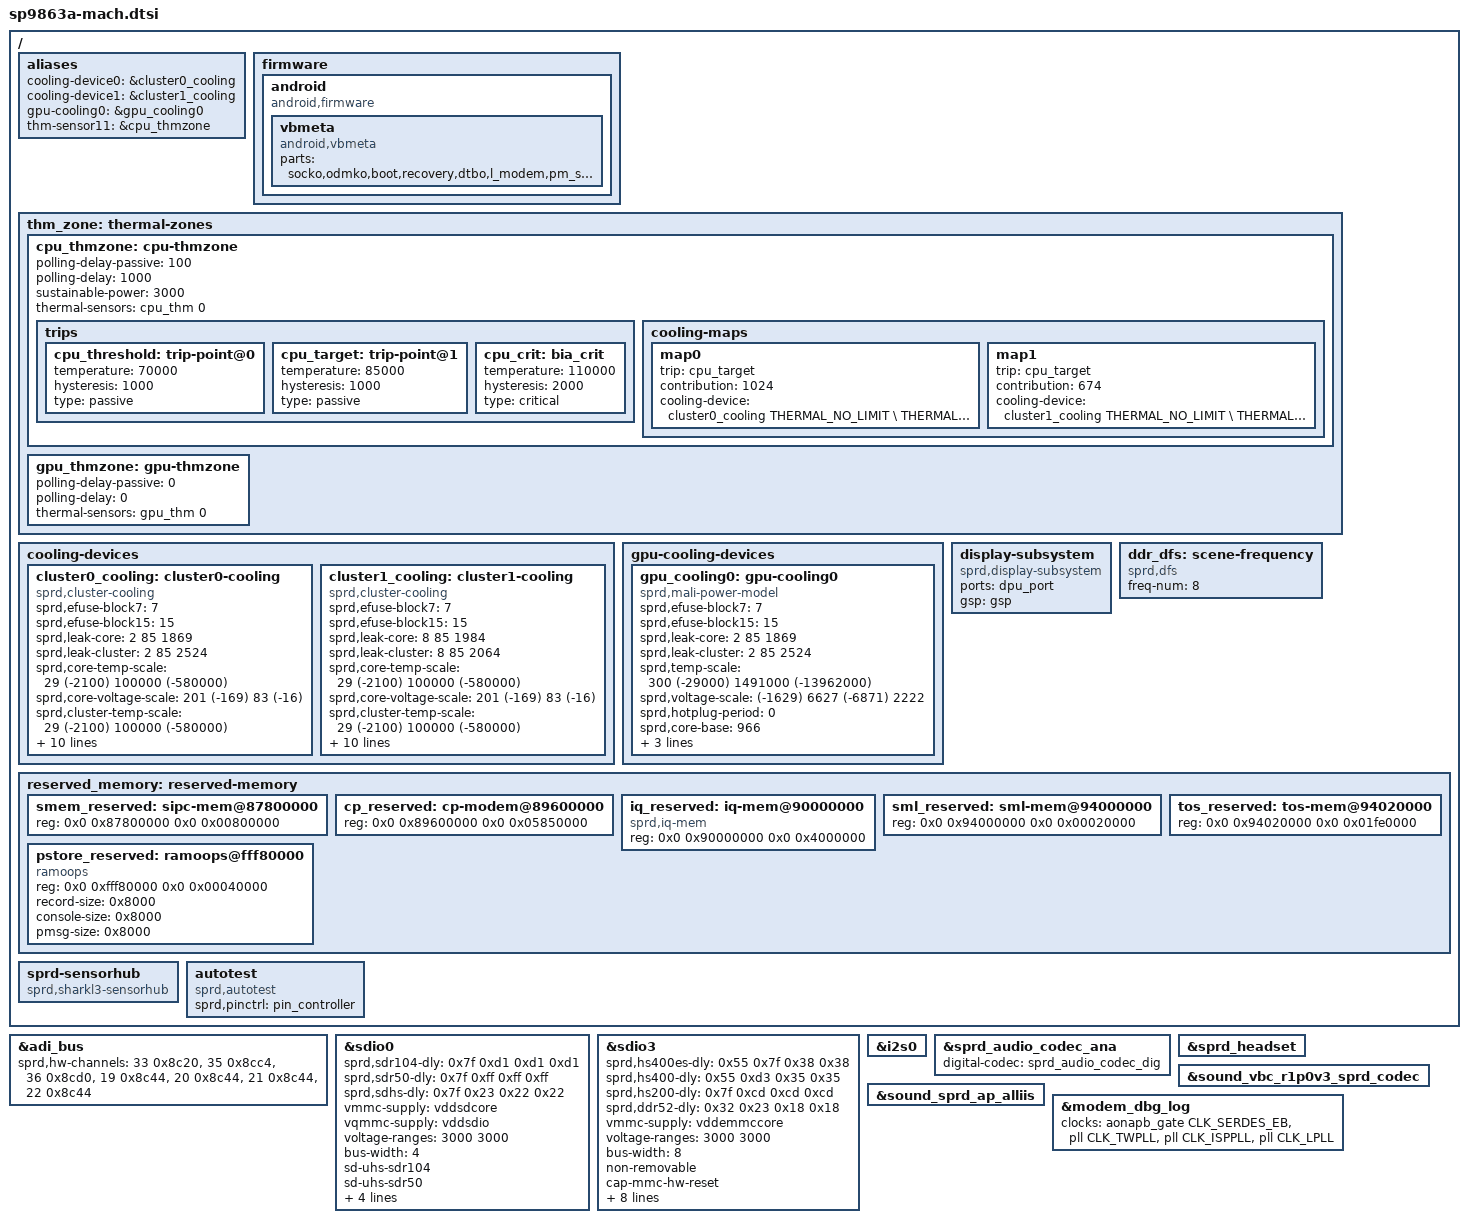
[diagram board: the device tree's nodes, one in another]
/*
 * Spreadtrum SP9863A board common DTS file
 *
 * Copyright (C) 2017, Spreadtrum Communications Inc.
 *
 * This file is licensed under a dual GPLv2 or X11 license.
 */

#include "sc9863a-modem.dtsi"
#include "sc2721.dtsi"
#include "lcd/lcd_dummy_mipi.dtsi"
#include "sprd-sound-sharkl.dtsi"
#include <dt-bindings/thermal/thermal.h>

/ {
	aliases {
		cooling-device0 = &cluster0_cooling;
		cooling-device1 = &cluster1_cooling;
		gpu-cooling0 = &gpu_cooling0;
		thm-sensor11 = &cpu_thmzone;
	};

	firmware {
		android {
			compatible = "android,firmware";
			vbmeta {
				compatible = "android,vbmeta";
				parts = "socko,odmko,boot,recovery,dtbo,l_modem,pm_sys,l_ldsp,l_gdsp";
			};
		};
	};

	thm_zone: thermal-zones {

		cpu_thmzone: cpu-thmzone {
			polling-delay-passive = <100>;
			polling-delay = <1000>;
			sustainable-power = <3000>;
			thermal-sensors = <&cpu_thm  0>;
			trips {
				cpu_threshold: trip-point@0 {
					temperature = <70000>;
					hysteresis = <1000>;
					type = "passive";
				};
				cpu_target: trip-point@1 {
					temperature = <85000>;
					hysteresis = <1000>;
					type = "passive";
				};
				cpu_crit: bia_crit {
					temperature = <110000>;
					hysteresis = <2000>;
					type = "critical";
				};
			};
			cooling-maps {
				map0 {
					trip = <&cpu_target>;
					contribution = <1024>;
					cooling-device =
					<&cluster0_cooling THERMAL_NO_LIMIT \
					THERMAL_NO_LIMIT>;
				};
				map1 {
					trip = <&cpu_target>;
					contribution = <674>;
					cooling-device =
					<&cluster1_cooling THERMAL_NO_LIMIT \
					THERMAL_NO_LIMIT>;
				};
			};
		};

		gpu_thmzone: gpu-thmzone {
			polling-delay-passive = <0>;
			polling-delay = <0>;
			thermal-sensors = <&gpu_thm  0>;
		};
	};

	cooling-devices {
		cluster0_cooling: cluster0-cooling {
			compatible = "sprd,cluster-cooling";
			#cooling-cells = <2>; /* min followed by max */
			sprd,efuse-block7 = <7>;
			sprd,efuse-block15 = <15>;
			/* core_leak =                             */
			/*(LIT_LEAK[4:0]+1) x 2mA x 0.85V x 18.69% */
			sprd,leak-core = <2 85 1869>;
			/* cluster_leak =                           */
			/* (LIT_LEAK[4:0]+1) x 2mA x 0.85V x 25.24% */
			sprd,leak-cluster = <2 85 2524>;
			/*core Tscale = aT^3 + bT^2 + cT +di   */
			sprd,core-temp-scale =
			/* a*10^7   b*10^7      c*10^7     d*10^7 */
			<  29      (-2100)      100000    (-580000)>;
			/*core Vscale = eV^3 + fV^2 + gV + h */
			sprd,core-voltage-scale =
			/* e*10^2   f*10^2     g*10^2  h*10^2*/
			<  201     (-169)      83      (-16)>;
			/*cluster Tscale = aT^3 + bT^2 + cT +di   */
			sprd,cluster-temp-scale =
			/* a*10^7   b*10^7      c*10^7     d*10^7 */
			<  29      (-2100)      100000    (-580000)>;
			/*cluster Vscale = eV^3 + fV^2 + gV + h */
			sprd,cluster-voltage-scale =
			/* e*10^2   f*10^2     g*10^2  h*10^2*/
			<  201     (-169)      83      (-16)>;
			sprd,efuse-switch = <0>;
			sprd,hotplug-period = <10>;
			sprd,min-cpufreq = <768000>;
			sprd,min-cpunum = <4>;
			sprd,core-base = <2400>;
			sprd,cluster-base = <3970>;
			sprd,dynamic-core =
			/*Pdynperghz*10    Freq     Vbase  */
			< 1007           1000     1000>;
			sprd,dynamic-cluster =
			/*Pdynperghz*10    Freq     Vbase  */
			< 747           1000     1000>;
		};
		cluster1_cooling: cluster1-cooling {
			compatible = "sprd,cluster-cooling";
			#cooling-cells = <2>; /* min followed by max */
			sprd,efuse-block7 = <7>;
			sprd,efuse-block15 = <15>;
			/* core_leak =                             */
			/*(LIT_LEAK[4:0]+1) x 2mA x 0.85V x 18.69% */
			sprd,leak-core = <8 85 1984>;
			/* cluster_leak =                           */
			/* (LIT_LEAK[4:0]+1) x 2mA x 0.85V x 25.24% */
			sprd,leak-cluster = <8 85 2064>;
			/*core Tscale = aT^3 + bT^2 + cT +d  */
			sprd,core-temp-scale =
			/* a*10^7   b*10^7	c*10^7	   d*10^7*/
			<  29      (-2100)      100000    (-580000)>;
			/* core  Vscale = eV^3 + fV^2 + gV + h */
			sprd,core-voltage-scale =
			/* e*10^2  f*10^2     g*10^2  h*10^2*/
			<  201     (-169)      83      (-16)>;
			/*cluster Tscale = aT^3 + bT^2 + cT +di   */
			sprd,cluster-temp-scale =
			/* a*10^7   b*10^7      c*10^7     d*10^7 */
			<  29      (-2100)      100000    (-580000)>;
			/*cluster Vscale = eV^3 + fV^2 + gV + h */
			sprd,cluster-voltage-scale =
			/* e*10^2   f*10^2     g*10^2  h*10^2*/
			<  201     (-169)      83      (-16)>;
			sprd,efuse-switch = <0>;
			sprd,hotplug-period = <10>;
			sprd,min-cpufreq = <768000>;
			sprd,min-cpunum = <0>;
			sprd,core-base = <4190>;
			sprd,cluster-base = <3970>;
			sprd,dynamic-core =
			/* Pdynperghz*10    Freq     Vbase */
			<  1536          1000     1000>;
			sprd,dynamic-cluster =
			/* Pdynperghz*10    Freq     Vbase */
			<  747            1000     1000>;
		};
	};

	gpu-cooling-devices {
		gpu_cooling0: gpu-cooling0 {
			compatible = "sprd,mali-power-model";
			#cooling-cells = <2>;
			sprd,efuse-block7 = <7>;
			sprd,efuse-block15 = <15>;
			/* core_leak =                             */
			/*(LIT_LEAK[4:0]+1) x 2mA x 0.85V x 18.69% */
			sprd,leak-core = <2 85 1869>;
			/* cluster_leak =                           */
			/* (LIT_LEAK[4:0]+1) x 2mA x 0.85V x 25.24% */
			sprd,leak-cluster = <2 85 2524>;
			/*Tscale = aT^3 + bT^2 + cT +di   */
			sprd,temp-scale =
			/* a*10^7   b*10^7      c*10^7     d*10^7 */
			<  300     (-29000)     1491000    (-13962000)>;
			/*Vscale = eV^3 + fV^2 + gV + h */
			sprd,voltage-scale =
			/* e*10^2   f*10^2     g*10^2      h*10^2*/
			<  (-1629)  6627       (-6871)     2222>;
			sprd,hotplug-period = <0>;
			sprd,core-base = <966>;
			sprd,cluster-base = <966>;
			sprd,dynamic-core =
			/*Pdynperghz    Freq     Vbase  */
			< 6046           768     900>;
			sprd,dynamic-cluster =
			/*Pdynperghz    Freq     Vbase  */
			< 6064           768     900>;
		};
	};

	display-subsystem {
		compatible = "sprd,display-subsystem";
		ports = <&dpu_port>;
		gsp = <&gsp>;
	};

	ddr_dfs: scene-frequency {
		compatible = "sprd,dfs";
		freq-num = <8>;
	};

	reserved_memory: reserved-memory {
		#address-cells = <2>;
		#size-cells = <2>;
		ranges;

		smem_reserved: sipc-mem@87800000{
			reg = <0x0 0x87800000 0x0 0x00800000>;
		};

		cp_reserved: cp-modem@89600000 {
			reg = <0x0 0x89600000 0x0 0x05850000>;
		};

		/* Only used for iq, will be removed in normal mode by uboot */
		iq_reserved: iq-mem@90000000 {
			compatible = "sprd,iq-mem";
			reg = <0x0 0x90000000 0x0 0x4000000>;
		};

		/* must be 1M aligned */
		sml_reserved: sml-mem@94000000 {
			reg = <0x0 0x94000000 0x0 0x00020000>;
		};

		tos_reserved: tos-mem@94020000{
			reg = <0x0 0x94020000 0x0 0x01fe0000>;
		};

		pstore_reserved: ramoops@fff80000 {
			compatible = "ramoops";
			reg = <0x0 0xfff80000 0x0 0x00040000>;
			record-size = <0x8000>;
			console-size = <0x8000>;
			pmsg-size = <0x8000>;
		};
	};

	sprd-sensorhub {
		compatible = "sprd,sharkl3-sensorhub";
	};

	autotest: autotest {
		compatible = "sprd,autotest";
		sprd,pinctrl = <&pin_controller>;
	};
};

&adi_bus {
	sprd,hw-channels = <33 0x8c20>, <35 0x8cc4>, <36 0x8cd0>, <19 0x8c44>, <20 0x8c44>, <21 0x8c44>, <22 0x8c44>;
};

&sdio0 {
	sprd,sdr104-dly = <0x7f 0xd1 0xd1 0xd1>;
	sprd,sdr50-dly = <0x7f 0xff 0xff 0xff>;
	sprd,sdhs-dly = <0x7f 0x23 0x22 0x22>;
	vmmc-supply = <&vddsdcore>;
	vqmmc-supply = <&vddsdio>;
	voltage-ranges = <3000 3000>;
	bus-width = <4>;
	sd-uhs-sdr104;
	sd-uhs-sdr50;
	sprd,name = "sdio_sd";
	sprd,sdio-adma;
	no-sdio;
	no-mmc;
	status = "okay";
};

&sdio3 {
	sprd,hs400es-dly = <0x55 0x7f 0x38 0x38>;
	sprd,hs400-dly = <0x55 0xd3 0x35 0x35>;
	sprd,hs200-dly = <0x7f 0xcd 0xcd 0xcd>;
	sprd,ddr52-dly = <0x32 0x23 0x18 0x18>;
	vmmc-supply = <&vddemmccore>;
	voltage-ranges = <3000 3000>;
	bus-width = <8>;
	non-removable;
	cap-mmc-hw-reset;
	mmc-hs400-enhanced-strobe;
	mmc-hs400-1_8v;
	mmc-hs200-1_8v;
	mmc-ddr-1_8v;
	sprd,name = "sdio_emmc";
	sprd,sdio-adma;
	no-sdio;
	no-sd;
	status = "okay";
};

&i2s0 {
	status = "okay";
};

&sprd_audio_codec_ana {
	status = "okay";
	digital-codec = <&sprd_audio_codec_dig>;
};

&sprd_headset {
	status = "okay";
};

&sound_vbc_r1p0v3_sprd_codec {
	status = "okay";
};

&sound_sprd_ap_alliis {
	status = "okay";
};

&modem_dbg_log {
	status = "okay";
	clock-names = "serdes_eb", "src0", "src1", "src2";
	clocks = <&aonapb_gate CLK_SERDES_EB>, <&pll CLK_TWPLL>, <&pll CLK_ISPPLL>, <&pll CLK_LPLL>;
};
